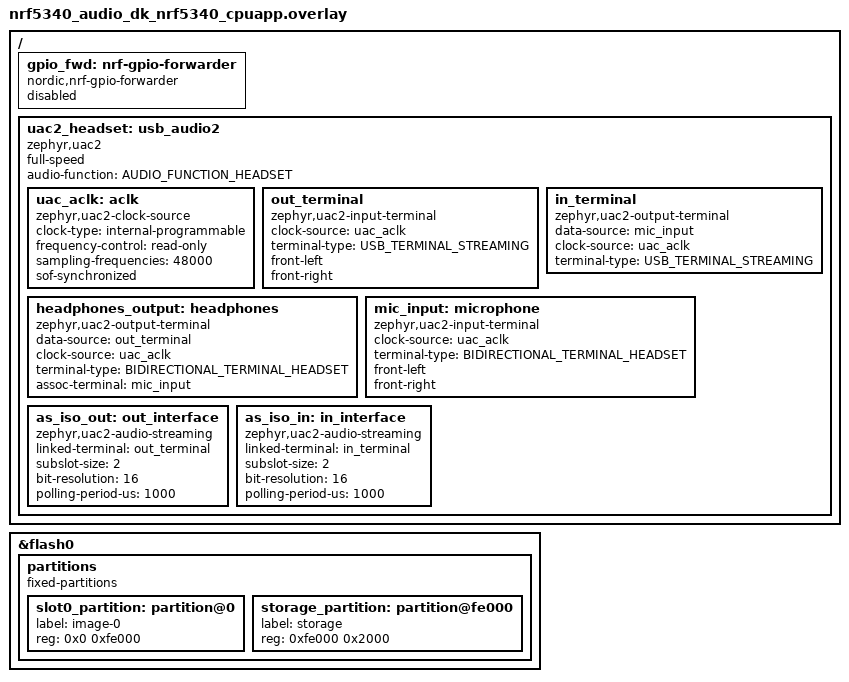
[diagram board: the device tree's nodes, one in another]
/*
 * Copyright (c) 2024 Nordic Semiconductor ASA
 *
 * SPDX-License-Identifier: LicenseRef-Nordic-5-Clause
 */

#include <dt-bindings/usb/audio.h>

/ {
	gpio_fwd: nrf-gpio-forwarder {
		compatible = "nordic,nrf-gpio-forwarder";
		status = "disabled";
	};
};

/* The base board DTS (nrf5340_audio_dk_nrf5340_cpuapp_common.dtsi) defines a
 * legacy UAC1 `hs_0` (usb-audio-hs) node under &usbd. Remove it and replace it
 * with a UAC2 node so this board matches the other targets. The base DTS is
 * shared and must not be edited, so the override happens here.
 */
/delete-node/ &hs_0;

/* UAC2 (USB Audio Class 2.0) headset device — required by audio_usb.c
 * (DT_NODELABEL(uac2_headset)). Full-Speed on the nRF5340 usbd controller.
 */
/ {
	uac2_headset: usb_audio2 {
		compatible = "zephyr,uac2";
		status = "okay";
		full-speed;
		audio-function = <AUDIO_FUNCTION_HEADSET>;

		uac_aclk: aclk {
			compatible = "zephyr,uac2-clock-source";
			clock-type = "internal-programmable";
			frequency-control = "read-only";
			sampling-frequencies = <48000>;
			sof-synchronized;
		};

		out_terminal: out_terminal {
			compatible = "zephyr,uac2-input-terminal";
			clock-source = <&uac_aclk>;
			terminal-type = <USB_TERMINAL_STREAMING>;
			front-left;
			front-right;
		};

		headphones_output: headphones {
			compatible = "zephyr,uac2-output-terminal";
			data-source = <&out_terminal>;
			clock-source = <&uac_aclk>;
			terminal-type = <BIDIRECTIONAL_TERMINAL_HEADSET>;
			assoc-terminal = <&mic_input>;
		};

		in_terminal: in_terminal {
			compatible = "zephyr,uac2-output-terminal";
			data-source = <&mic_input>;
			clock-source = <&uac_aclk>;
			terminal-type = <USB_TERMINAL_STREAMING>;
		};

		mic_input: microphone {
			compatible = "zephyr,uac2-input-terminal";
			clock-source = <&uac_aclk>;
			terminal-type = <BIDIRECTIONAL_TERMINAL_HEADSET>;
			front-left;
			front-right;
		};

		as_iso_out: out_interface {
			compatible = "zephyr,uac2-audio-streaming";
			linked-terminal = <&out_terminal>;
			subslot-size = <2>;
			bit-resolution = <16>;
			polling-period-us = <1000>;
		};

		as_iso_in: in_interface {
			compatible = "zephyr,uac2-audio-streaming";
			linked-terminal = <&in_terminal>;
			subslot-size = <2>;
			bit-resolution = <16>;
			polling-period-us = <1000>;
		};
	};
};

/* Override default MCUboot partition table with a single-image (no bootloader)
 * layout that matches the legacy Partition Manager layout:
 *   slot0_partition : 0x000000 - 0x0fdfff  (1016 KB, app image)
 *   storage_partition: 0x0fe000 - 0x0fffff  (8 KB = 2 ZMS sectors, NVS/settings)
 * storage was shrunk 16 KB -> 8 KB to give the app +8 KB so the P2P image
 * still fits with the Wi-Fi shell enabled. 8 KB (2 x 4 KB sectors) is the ZMS
 * minimum; it holds the Wi-Fi mode byte + a few stored credentials.
 */
&flash0 {
	/delete-node/ partitions;

	partitions {
		compatible = "fixed-partitions";
		#address-cells = <1>;
		#size-cells = <1>;

		slot0_partition: partition@0 {
			label = "image-0";
			reg = <0x0 0xfe000>;
		};

		storage_partition: partition@fe000 {
			label = "storage";
			reg = <0xfe000 0x2000>;
		};
	};
};
